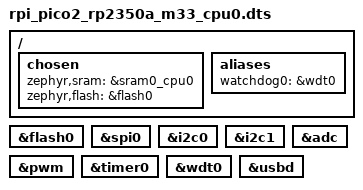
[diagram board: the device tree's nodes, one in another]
/*
 * Copyright (c) 2024 Andrew Featherstone
 *
 * SPDX-License-Identifier: Apache-2.0
 */

/dts-v1/;

/* The build system assumes that there's a cpucluster-specific file.
 *
 * This file provides composition of the device tree:
 * 1. The common features of the SoC
 * 2. Core-specific configuration.
 * 3. Board-specific configuration.
 */
#include <raspberrypi/rpi_pico/rp2350a.dtsi>
#include <raspberrypi/rpi_pico/m33.dtsi>

/* there's nothing specific to the Cortex-M33 cores vs the (not yet
 * implemented) Hazard3 cores.
 */
#include "rpi_pico2.dtsi"
#include "rpi_pico2_split.dtsi"

/delete-node/ &cpu1;

/ {
	chosen {
		zephyr,sram = &sram0_cpu0;
		zephyr,flash = &flash0;
		// TODO: partition the flash
		// zephyr,code-partition = &code_partition_cpu0;
	};

	aliases {
		watchdog0 = &wdt0;
	};
};

&flash0 {
	status = "okay";
};

&spi0 {
	status = "okay";
};

&i2c0 {
	status = "okay";
};

&i2c1 {
	status = "okay";
};

&adc {
	status = "okay";
};

&pwm {
	status = "okay";
};

&timer0 {
	status = "okay";
};

&wdt0 {
	status = "okay";
};

zephyr_udc0: &usbd {
	status = "okay";
};

// Let CPU1 use USB, while CPU0 uses UART0
#include <../boards/common/usb/cdc_acm_serial.dtsi>
